# PIC32CX5109BZ31032 device description
Architecture: CORTEX-M4; Family: PIC32CX; Series: PIC32CXBZ31
Registers are 32-bit, read-write, reset 0x0 unless marked. A register's access mark holds for its fields unless they carry their own. Offsets are from the block's base; [hi:lo] are bit positions; {n}, {i} and the like mark numbered series.

## CoreDebug
Instances: CoreDebug 0xE000EDF0
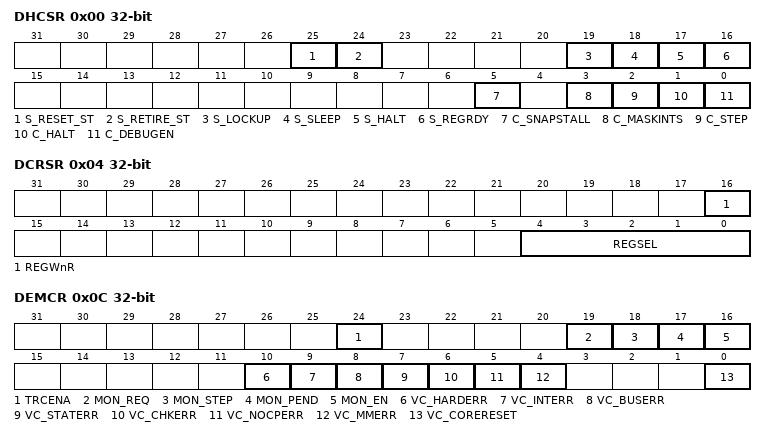
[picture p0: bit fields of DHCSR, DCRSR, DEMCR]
0x00 DHCSR reset not defined — Debug Halting Control and Status Register
  [25] S_RESET_ST, [24] S_RETIRE_ST, [19] S_LOCKUP, [18] S_SLEEP, [17] S_HALT, [16] S_REGRDY, [5] C_SNAPSTALL, [3] C_MASKINTS, [2] C_STEP, [1] C_HALT, [0] C_DEBUGEN
0x04 DCRSR wo reset not defined — Debug Core Register Selector Register
  [16] REGWnR, [4:0] REGSEL
0x08 DCRDR reset not defined — Debug Core Register Data Register
0x0C DEMCR reset not defined — Debug Exception and Monitor Control Register
  [24] TRCENA, [19] MON_REQ, [18] MON_STEP, [17] MON_PEND, [16] MON_EN, [10] VC_HARDERR, [9] VC_INTERR, [8] VC_BUSERR, [7] VC_STATERR, [6] VC_CHKERR, [5] VC_NOCPERR, [4] VC_MMERR, [0] VC_CORERESET

## DAC_CTRL — Descriptive Title of Macro
Instances: DAC_CTRL 0x44003C00
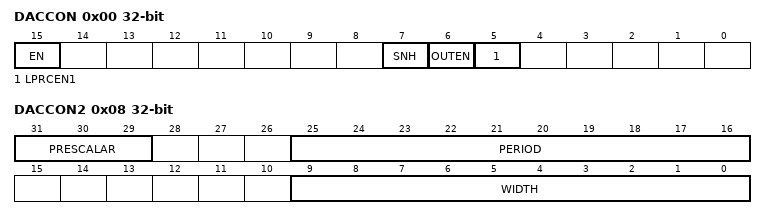
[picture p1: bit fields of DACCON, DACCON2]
0x00 DACCON — CONTROL Register
  [15] EN — Enable
    0=DAC_DISABLE (The peripheral is disabled.); 1=DAC_ENABLE (The peripheral is enabled.)
  [7] SNH — Sample and hold circuitry
    0=SNH_NORMAL (DAC operation in normal mode); 1=SNH_LOWPOWER (DAC operation in low power mode)
  [6] OUTEN — Will enable the output buffer
    0=OUTEN_DISABLE (Output buffer disabled); 1=OUTEN_ENABLE (Output buffer enabled)
  [5] LPRCEN1 — LPRC clock enabled for SnH mode
    0=LPRC_ENABLE (LPRC clock not enabled); 1=LPRC_DISABLE (LPRC clock enabled)
0x04 DACCODE
  [6:0] DATA — DAC data
0x08 DACCON2 — DAC Config register1
  [31:29] PRESCALAR — Prescaling factor for SnH clock
  [25:16] PERIOD — SnH clock period
  [9:0] WIDTH — SnH clock width

## DSU — Device Service Unit
Instances: DSU 0x41000000
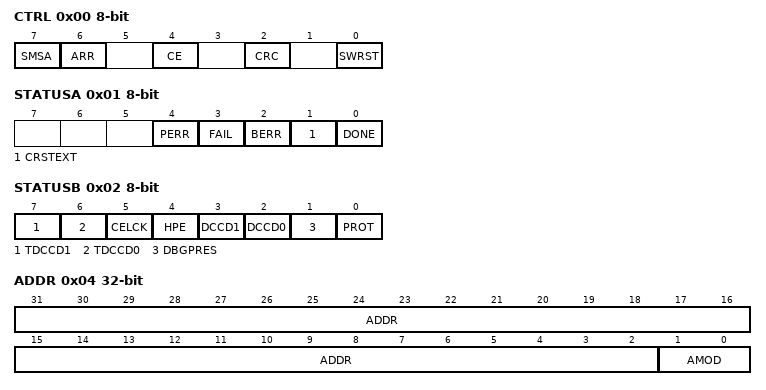
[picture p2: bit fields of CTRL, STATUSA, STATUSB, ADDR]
0x00 CTRL 8-bit wo — Control
  [7] SMSA — Start Memory Stream Access
  [6] ARR — Auxiliary Row Read
  [4] CE — Chip-Erase
  [2] CRC — 32-bit Cyclic Redundancy Code
  [0] SWRST — Software Reset
0x01 STATUSA 8-bit
  [4] PERR — Protection Error
  [3] FAIL — Failure
  [2] BERR — Bus Error
  [1] CRSTEXT — CPU Reset Phase Extension
  [0] DONE
0x02 STATUSB 8-bit ro
  [7] TDCCD1 — Test Debug Communication Channel 1 Dirty
  [6] TDCCD0 — Test Debug Communication Channel 0 Dirty
  [5] CELCK — Chip Erase Locked
  [4] HPE — Hot-Plugging Enable
  [3] DCCD1 — Debug Communication Channel 1 Dirty
  [2] DCCD0 — Debug Communication Channel 0 Dirty
  [1] DBGPRES — Debugger Present
  [0] PROT — Protected
0x04 ADDR — Address
  [31:2] ADDR — Address
  [1:0] AMOD — Access Mode
0x08 LENGTH
  [31:2] LENGTH
0x0C DATA
{0x10+4i} DCC[{i}] (i=0..1) — Debug Communication Channel n
  [31:0] DATA
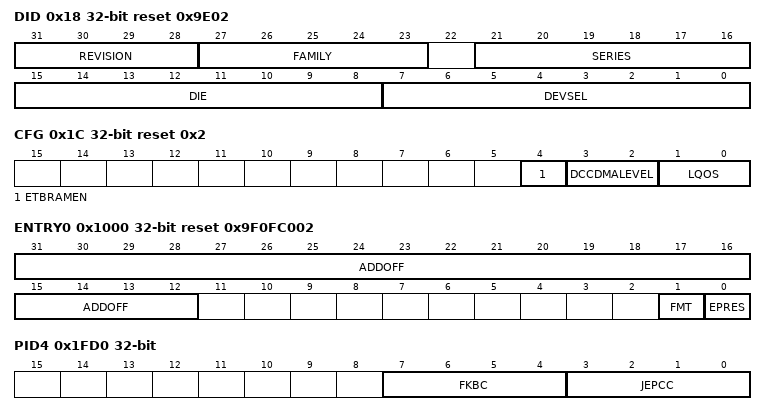
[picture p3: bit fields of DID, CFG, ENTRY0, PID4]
0x18 DID ro reset 0x9E02 — Device Identification
  [31:28] REVISION — Revision Number
  [27:23] FAMILY
  [21:16] SERIES
  [15:8] DIE — Die Number
  [7:0] DEVSEL — Device Select
0x1C CFG reset 0x2 — Configuration
  [4] ETBRAMEN — Trace Control
  [3:2] DCCDMALEVEL — DMA Trigger Level
    0=EMPTY (Trigger rises when DCC is empty); 1=FULL (Trigger rises when DCC is full)
  [1:0] LQOS — Latency Quality Of Service
{0x38+4i} UUID[{i}] (i=0..3) ro — Unique Identifier n
0x48 SECCFG ro — Secure Config
0x4C CTR_STAT ro — RoT Rollback counter
  [7:0] ROLLBACK_CTR — Rollback counter
0x50 BOOT_STAT ro — RoT Boot Status
  [7:0] BOOT_STATUS
{0x54+4i} BOOT_KEY[{i}] (i=0..11) ro — Secure Boot Key n
  [31:0] BOOT_KEY — Secure Boot Key
{0xF0+4i} DCFG[{i}] (i=0..1) — Device Configuration
0x1000 ENTRY0 ro reset 0x9F0FC002 — CoreSight ROM Table Entry 0
  [31:12] ADDOFF — Address Offset
  [1] FMT — Format
  [0] EPRES — Entry Present
0x1004 ENTRY1 ro — CoreSight ROM Table Entry 1
0x1008 END ro — CoreSight ROM Table End
  [31:0] END — End Marker
0x1FCC MEMTYPE ro — CoreSight ROM Table Memory Type
  [0] SMEMP — System Memory Present
0x1FD0 PID4 ro — Peripheral Identification 4
  [7:4] FKBC — 4KB count
  [3:0] JEPCC — JEP-106 Continuation Code
0x1FE0 PID0 ro reset 0xD0 — Peripheral Identification 0
  [7:0] PARTNBL — Part Number Low
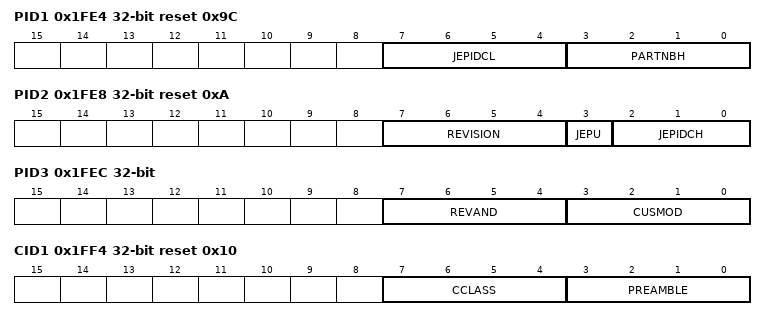
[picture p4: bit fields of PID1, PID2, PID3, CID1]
0x1FE4 PID1 ro reset 0x9C — Peripheral Identification 1
  [7:4] JEPIDCL — Low part of the JEP-106 Identity Code
  [3:0] PARTNBH — Part Number High
0x1FE8 PID2 ro reset 0xA — Peripheral Identification 2
  [7:4] REVISION — Revision Number
  [3] JEPU — JEP-106 Identity Code is used
  [2:0] JEPIDCH — JEP-106 Identity Code High
0x1FEC PID3 ro — Peripheral Identification 3
  [7:4] REVAND — Revision Number
  [3:0] CUSMOD — ARM CUSMOD
0x1FF0 CID0 ro reset 0xD — Component Identification 0
  [7:0] PREAMBLEB0 — Preamble Byte 0
0x1FF4 CID1 ro reset 0x10 — Component Identification 1
  [7:4] CCLASS — Component Class
  [3:0] PREAMBLE
0x1FF8 CID2 ro reset 0x5 — Component Identification 2
  [7:0] PREAMBLEB2 — Preamble Byte 2
0x1FFC CID3 ro reset 0xB1 — Component Identification 3
  [7:0] PREAMBLEB3 — Preamble Byte 3

## Notices in the file
Copyright (c) 2021 Microchip Technology Inc.
SPDX-License-Identifier: Apache-2.0
Licensed under the Apache License, Version 2.0 (the "License");
you may not use this file except in compliance with the License.
You may obtain a copy of the License at
http://www.apache.org/licenses/LICENSE-2.0
Unless required by applicable law or agreed to in writing, software
distributed under the License is distributed on an "AS IS" BASIS,
WITHOUT WARRANTIES OR CONDITIONS OF ANY KIND, either express or implied.
See the License for the specific language governing permissions and
limitations under the License.
